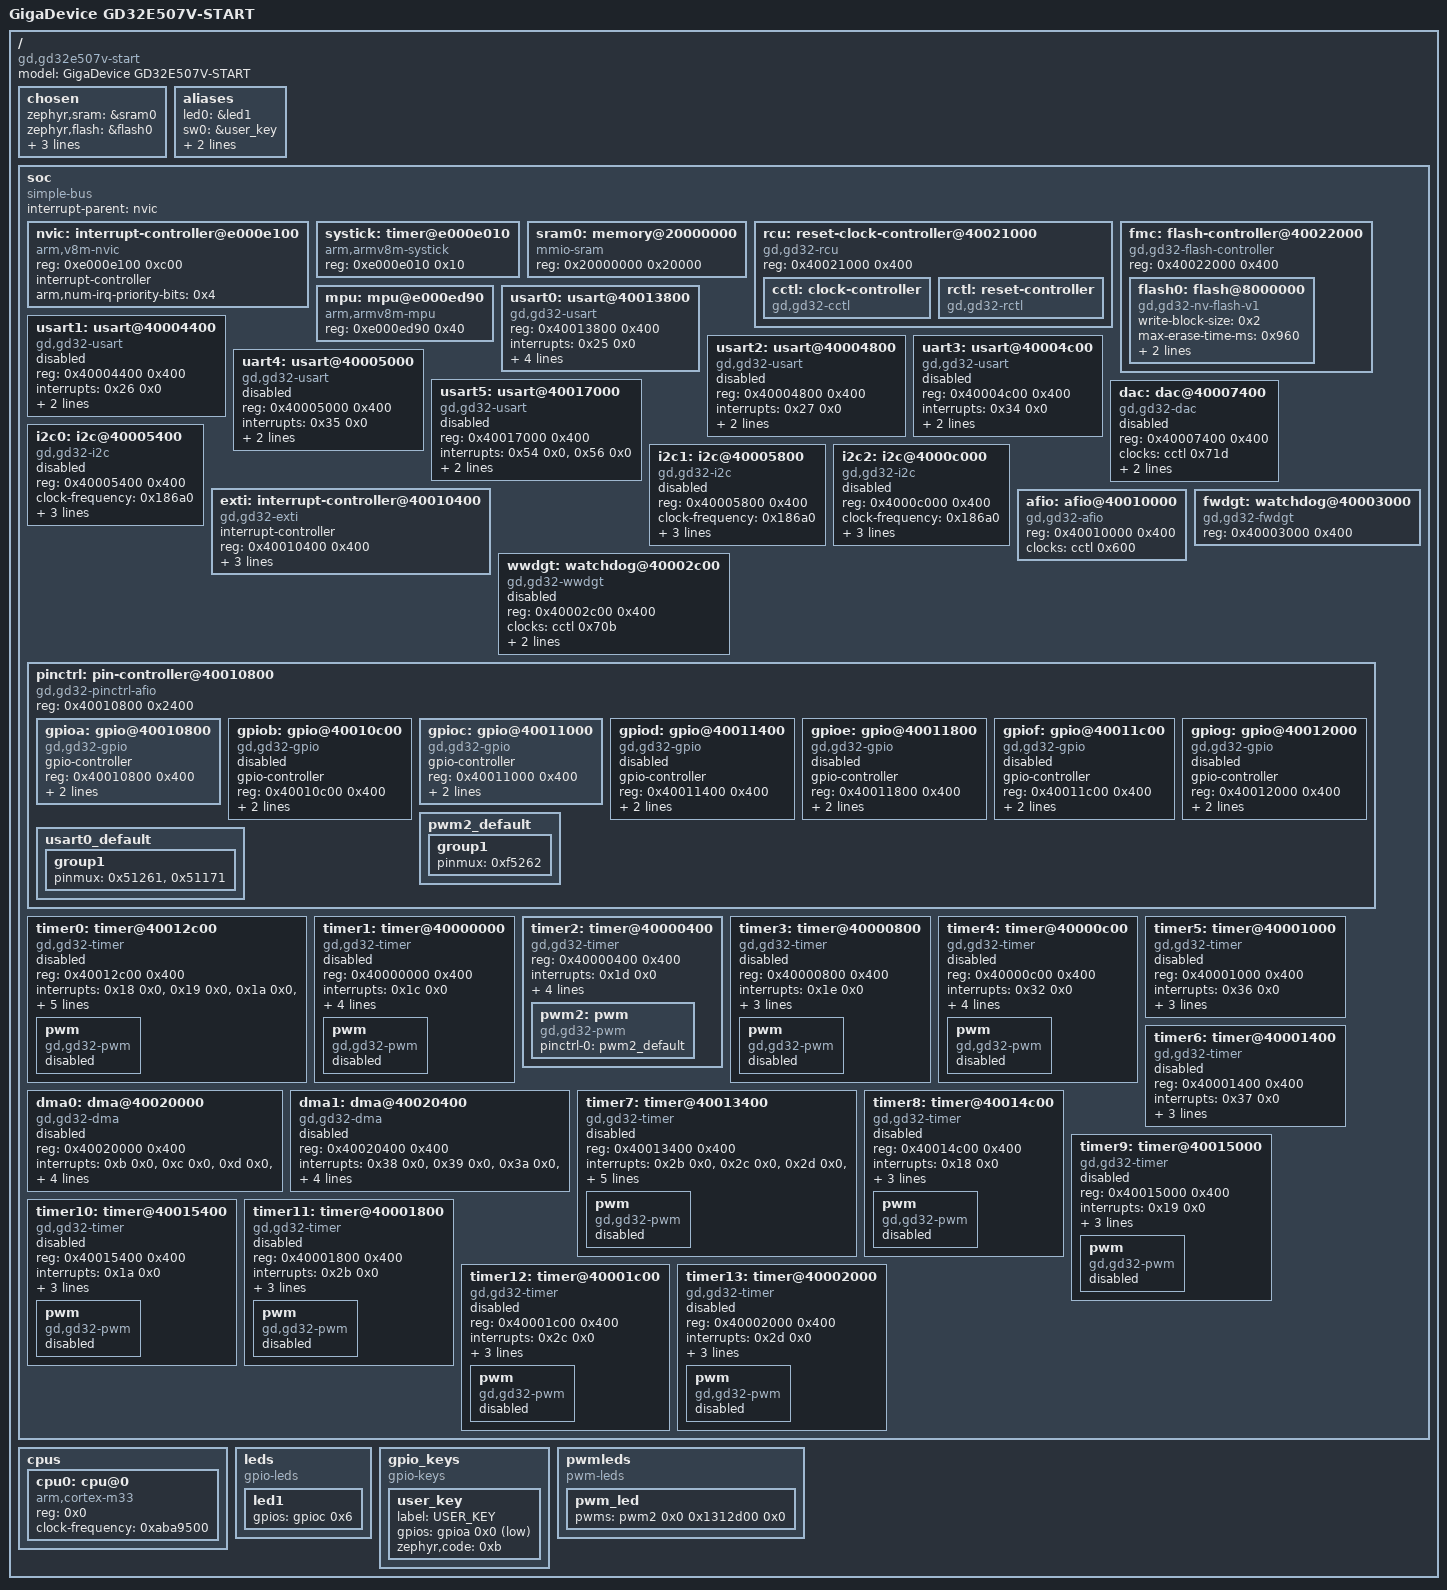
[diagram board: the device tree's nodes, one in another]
/dts-v1/;

/* node '/' defined in zephyr/dts/common/skeleton.dtsi:9 */
/ {
	#address-cells = < 0x1 >;             /* in zephyr/dts/common/skeleton.dtsi:10 */
	#size-cells = < 0x1 >;                /* in zephyr/dts/common/skeleton.dtsi:11 */
	model = "GigaDevice GD32E507V-START"; /* in zephyr/boards/gd/gd32e507v_start/gd32e507v_start.dts:13 */
	compatible = "gd,gd32e507v-start";    /* in zephyr/boards/gd/gd32e507v_start/gd32e507v_start.dts:14 */

	/* node '/chosen' defined in zephyr/dts/common/skeleton.dtsi:13 */
	chosen {
		zephyr,sram = &sram0;           /* in zephyr/boards/gd/gd32e507v_start/gd32e507v_start.dts:17 */
		zephyr,flash = &flash0;         /* in zephyr/boards/gd/gd32e507v_start/gd32e507v_start.dts:18 */
		zephyr,console = &usart0;       /* in zephyr/boards/gd/gd32e507v_start/gd32e507v_start.dts:19 */
		zephyr,shell-uart = &usart0;    /* in zephyr/boards/gd/gd32e507v_start/gd32e507v_start.dts:20 */
		zephyr,flash-controller = &fmc; /* in zephyr/boards/gd/gd32e507v_start/gd32e507v_start.dts:21 */
	};

	/* node '/aliases' defined in zephyr/dts/common/skeleton.dtsi:15 */
	aliases {
		led0 = &led1;        /* in zephyr/boards/gd/gd32e507v_start/gd32e507v_start.dts:51 */
		sw0 = &user_key;     /* in zephyr/boards/gd/gd32e507v_start/gd32e507v_start.dts:52 */
		pwm-led0 = &pwm_led; /* in zephyr/boards/gd/gd32e507v_start/gd32e507v_start.dts:53 */
		watchdog0 = &fwdgt;  /* in zephyr/boards/gd/gd32e507v_start/gd32e507v_start.dts:54 */
	};

	/* node '/soc' defined in zephyr/dts/arm/armv8-m.dtsi:6 */
	soc {
		#address-cells = < 0x1 >;     /* in zephyr/dts/arm/armv8-m.dtsi:7 */
		#size-cells = < 0x1 >;        /* in zephyr/dts/arm/armv8-m.dtsi:8 */
		compatible = "simple-bus";    /* in zephyr/dts/arm/armv8-m.dtsi:9 */
		interrupt-parent = < &nvic >; /* in zephyr/dts/arm/armv8-m.dtsi:10 */
		ranges;                       /* in zephyr/dts/arm/armv8-m.dtsi:11 */

		/* node '/soc/interrupt-controller@e000e100' defined in zephyr/dts/arm/armv8-m.dtsi:13 */
		nvic: interrupt-controller@e000e100 {
			#address-cells = < 0x1 >;            /* in zephyr/dts/arm/armv8-m.dtsi:14 */
			compatible = "arm,v8m-nvic";         /* in zephyr/dts/arm/armv8-m.dtsi:15 */
			reg = < 0xe000e100 0xc00 >;          /* in zephyr/dts/arm/armv8-m.dtsi:16 */
			interrupt-controller;                /* in zephyr/dts/arm/armv8-m.dtsi:17 */
			#interrupt-cells = < 0x2 >;          /* in zephyr/dts/arm/armv8-m.dtsi:18 */
			arm,num-irq-priority-bits = < 0x4 >; /* in zephyr/dts/arm/gd/gd32e50x/gd32e50x.dtsi:433 */
			phandle = < 0x1 >;                   /* in zephyr/dts/arm/armv8-m.dtsi:10 */
		};

		/* node '/soc/timer@e000e010' defined in zephyr/dts/arm/armv8-m.dtsi:21 */
		systick: timer@e000e010 {
			compatible = "arm,armv8m-systick"; /* in zephyr/dts/arm/armv8-m.dtsi:22 */
			reg = < 0xe000e010 0x10 >;         /* in zephyr/dts/arm/armv8-m.dtsi:23 */
		};

		/* node '/soc/memory@20000000' defined in zephyr/dts/arm/gd/gd32e50x/gd32e50x.dtsi:30 */
		sram0: memory@20000000 {
			compatible = "mmio-sram";     /* in zephyr/dts/arm/gd/gd32e50x/gd32e50x.dtsi:31 */
			reg = < 0x20000000 0x20000 >; /* in zephyr/dts/arm/gd/gd32e50x/gd32e507xe.dtsi:139 */
		};

		/* node '/soc/reset-clock-controller@40021000' defined in zephyr/dts/arm/gd/gd32e50x/gd32e50x.dtsi:34 */
		rcu: reset-clock-controller@40021000 {
			compatible = "gd,gd32-rcu"; /* in zephyr/dts/arm/gd/gd32e50x/gd32e50x.dtsi:35 */
			reg = < 0x40021000 0x400 >; /* in zephyr/dts/arm/gd/gd32e50x/gd32e50x.dtsi:36 */
			status = "okay";            /* in zephyr/dts/arm/gd/gd32e50x/gd32e50x.dtsi:37 */

			/* node '/soc/reset-clock-controller@40021000/clock-controller' defined in zephyr/dts/arm/gd/gd32e50x/gd32e50x.dtsi:39 */
			cctl: clock-controller {
				compatible = "gd,gd32-cctl"; /* in zephyr/dts/arm/gd/gd32e50x/gd32e50x.dtsi:40 */
				#clock-cells = < 0x1 >;      /* in zephyr/dts/arm/gd/gd32e50x/gd32e50x.dtsi:41 */
				status = "okay";             /* in zephyr/dts/arm/gd/gd32e50x/gd32e50x.dtsi:42 */
				phandle = < 0x2 >;           /* in zephyr/dts/arm/gd/gd32e50x/gd32e50x.dtsi:83 */
			};

			/* node '/soc/reset-clock-controller@40021000/reset-controller' defined in zephyr/dts/arm/gd/gd32e50x/gd32e50x.dtsi:45 */
			rctl: reset-controller {
				compatible = "gd,gd32-rctl"; /* in zephyr/dts/arm/gd/gd32e50x/gd32e50x.dtsi:46 */
				#reset-cells = < 0x1 >;      /* in zephyr/dts/arm/gd/gd32e50x/gd32e50x.dtsi:47 */
				status = "okay";             /* in zephyr/dts/arm/gd/gd32e50x/gd32e50x.dtsi:48 */
				phandle = < 0x3 >;           /* in zephyr/dts/arm/gd/gd32e50x/gd32e50x.dtsi:84 */
			};
		};

		/* node '/soc/flash-controller@40022000' defined in zephyr/dts/arm/gd/gd32e50x/gd32e50x.dtsi:52 */
		fmc: flash-controller@40022000 {
			compatible = "gd,gd32-flash-controller"; /* in zephyr/dts/arm/gd/gd32e50x/gd32e50x.dtsi:53 */
			reg = < 0x40022000 0x400 >;              /* in zephyr/dts/arm/gd/gd32e50x/gd32e50x.dtsi:54 */
			#address-cells = < 0x1 >;                /* in zephyr/dts/arm/gd/gd32e50x/gd32e50x.dtsi:56 */
			#size-cells = < 0x1 >;                   /* in zephyr/dts/arm/gd/gd32e50x/gd32e50x.dtsi:57 */

			/* node '/soc/flash-controller@40022000/flash@8000000' defined in zephyr/dts/arm/gd/gd32e50x/gd32e50x.dtsi:59 */
			flash0: flash@8000000 {
				compatible = "gd,gd32-nv-flash-v1",
				             "soc-nv-flash";        /* in zephyr/dts/arm/gd/gd32e50x/gd32e50x.dtsi:60 */
				write-block-size = < 0x2 >;         /* in zephyr/dts/arm/gd/gd32e50x/gd32e50x.dtsi:61 */
				max-erase-time-ms = < 0x960 >;      /* in zephyr/dts/arm/gd/gd32e50x/gd32e50x.dtsi:69 */
				page-size = < 0x2000 >;             /* in zephyr/dts/arm/gd/gd32e50x/gd32e50x.dtsi:70 */
				reg = < 0x8000000 0x80000 >;        /* in zephyr/dts/arm/gd/gd32e50x/gd32e507xe.dtsi:135 */
			};
		};

		/* node '/soc/mpu@e000ed90' defined in zephyr/dts/arm/gd/gd32e50x/gd32e50x.dtsi:74 */
		mpu: mpu@e000ed90 {
			compatible = "arm,armv8m-mpu"; /* in zephyr/dts/arm/gd/gd32e50x/gd32e50x.dtsi:75 */
			reg = < 0xe000ed90 0x40 >;     /* in zephyr/dts/arm/gd/gd32e50x/gd32e50x.dtsi:76 */
		};

		/* node '/soc/usart@40013800' defined in zephyr/dts/arm/gd/gd32e50x/gd32e50x.dtsi:79 */
		usart0: usart@40013800 {
			compatible = "gd,gd32-usart";    /* in zephyr/dts/arm/gd/gd32e50x/gd32e50x.dtsi:80 */
			reg = < 0x40013800 0x400 >;      /* in zephyr/dts/arm/gd/gd32e50x/gd32e50x.dtsi:81 */
			interrupts = < 0x25 0x0 >;       /* in zephyr/dts/arm/gd/gd32e50x/gd32e50x.dtsi:82 */
			clocks = < &cctl 0x60e >;        /* in zephyr/dts/arm/gd/gd32e50x/gd32e50x.dtsi:83 */
			resets = < &rctl 0x30e >;        /* in zephyr/dts/arm/gd/gd32e50x/gd32e50x.dtsi:84 */
			status = "okay";                 /* in zephyr/boards/gd/gd32e507v_start/gd32e507v_start.dts:67 */
			current-speed = < 0x1c200 >;     /* in zephyr/boards/gd/gd32e507v_start/gd32e507v_start.dts:68 */
			pinctrl-0 = < &usart0_default >; /* in zephyr/boards/gd/gd32e507v_start/gd32e507v_start.dts:69 */
			pinctrl-names = "default";       /* in zephyr/boards/gd/gd32e507v_start/gd32e507v_start.dts:70 */
		};

		/* node '/soc/usart@40004400' defined in zephyr/dts/arm/gd/gd32e50x/gd32e50x.dtsi:88 */
		usart1: usart@40004400 {
			compatible = "gd,gd32-usart"; /* in zephyr/dts/arm/gd/gd32e50x/gd32e50x.dtsi:89 */
			reg = < 0x40004400 0x400 >;   /* in zephyr/dts/arm/gd/gd32e50x/gd32e50x.dtsi:90 */
			interrupts = < 0x26 0x0 >;    /* in zephyr/dts/arm/gd/gd32e50x/gd32e50x.dtsi:91 */
			clocks = < &cctl 0x711 >;     /* in zephyr/dts/arm/gd/gd32e50x/gd32e50x.dtsi:92 */
			resets = < &rctl 0x411 >;     /* in zephyr/dts/arm/gd/gd32e50x/gd32e50x.dtsi:93 */
			status = "disabled";          /* in zephyr/dts/arm/gd/gd32e50x/gd32e50x.dtsi:94 */
		};

		/* node '/soc/usart@40004800' defined in zephyr/dts/arm/gd/gd32e50x/gd32e50x.dtsi:97 */
		usart2: usart@40004800 {
			compatible = "gd,gd32-usart"; /* in zephyr/dts/arm/gd/gd32e50x/gd32e50x.dtsi:98 */
			reg = < 0x40004800 0x400 >;   /* in zephyr/dts/arm/gd/gd32e50x/gd32e50x.dtsi:99 */
			interrupts = < 0x27 0x0 >;    /* in zephyr/dts/arm/gd/gd32e50x/gd32e50x.dtsi:100 */
			clocks = < &cctl 0x712 >;     /* in zephyr/dts/arm/gd/gd32e50x/gd32e50x.dtsi:101 */
			resets = < &rctl 0x412 >;     /* in zephyr/dts/arm/gd/gd32e50x/gd32e50x.dtsi:102 */
			status = "disabled";          /* in zephyr/dts/arm/gd/gd32e50x/gd32e50x.dtsi:103 */
		};

		/* node '/soc/usart@40004c00' defined in zephyr/dts/arm/gd/gd32e50x/gd32e50x.dtsi:106 */
		uart3: usart@40004c00 {
			compatible = "gd,gd32-usart"; /* in zephyr/dts/arm/gd/gd32e50x/gd32e50x.dtsi:107 */
			reg = < 0x40004c00 0x400 >;   /* in zephyr/dts/arm/gd/gd32e50x/gd32e50x.dtsi:108 */
			interrupts = < 0x34 0x0 >;    /* in zephyr/dts/arm/gd/gd32e50x/gd32e50x.dtsi:109 */
			clocks = < &cctl 0x713 >;     /* in zephyr/dts/arm/gd/gd32e50x/gd32e50x.dtsi:110 */
			resets = < &rctl 0x413 >;     /* in zephyr/dts/arm/gd/gd32e50x/gd32e50x.dtsi:111 */
			status = "disabled";          /* in zephyr/dts/arm/gd/gd32e50x/gd32e50x.dtsi:112 */
		};

		/* node '/soc/usart@40005000' defined in zephyr/dts/arm/gd/gd32e50x/gd32e50x.dtsi:115 */
		uart4: usart@40005000 {
			compatible = "gd,gd32-usart"; /* in zephyr/dts/arm/gd/gd32e50x/gd32e50x.dtsi:116 */
			reg = < 0x40005000 0x400 >;   /* in zephyr/dts/arm/gd/gd32e50x/gd32e50x.dtsi:117 */
			interrupts = < 0x35 0x0 >;    /* in zephyr/dts/arm/gd/gd32e50x/gd32e50x.dtsi:118 */
			clocks = < &cctl 0x714 >;     /* in zephyr/dts/arm/gd/gd32e50x/gd32e50x.dtsi:119 */
			resets = < &rctl 0x414 >;     /* in zephyr/dts/arm/gd/gd32e50x/gd32e50x.dtsi:120 */
			status = "disabled";          /* in zephyr/dts/arm/gd/gd32e50x/gd32e50x.dtsi:121 */
		};

		/* node '/soc/usart@40017000' defined in zephyr/dts/arm/gd/gd32e50x/gd32e50x.dtsi:124 */
		usart5: usart@40017000 {
			compatible = "gd,gd32-usart"; /* in zephyr/dts/arm/gd/gd32e50x/gd32e50x.dtsi:125 */
			reg = < 0x40017000 0x400 >;   /* in zephyr/dts/arm/gd/gd32e50x/gd32e50x.dtsi:126 */
			interrupts = < 0x54 0x0 >,
			             < 0x56 0x0 >;    /* in zephyr/dts/arm/gd/gd32e50x/gd32e50x.dtsi:127 */
			interrupt-names = "global",
			                  "wkup";     /* in zephyr/dts/arm/gd/gd32e50x/gd32e50x.dtsi:128 */
			clocks = < &cctl 0x61c >;     /* in zephyr/dts/arm/gd/gd32e50x/gd32e50x.dtsi:129 */
			resets = < &rctl 0x31c >;     /* in zephyr/dts/arm/gd/gd32e50x/gd32e50x.dtsi:130 */
			status = "disabled";          /* in zephyr/dts/arm/gd/gd32e50x/gd32e50x.dtsi:131 */
		};

		/* node '/soc/dac@40007400' defined in zephyr/dts/arm/gd/gd32e50x/gd32e50x.dtsi:134 */
		dac: dac@40007400 {
			compatible = "gd,gd32-dac";  /* in zephyr/dts/arm/gd/gd32e50x/gd32e50x.dtsi:135 */
			reg = < 0x40007400 0x400 >;  /* in zephyr/dts/arm/gd/gd32e50x/gd32e50x.dtsi:136 */
			clocks = < &cctl 0x71d >;    /* in zephyr/dts/arm/gd/gd32e50x/gd32e50x.dtsi:137 */
			resets = < &rctl 0x41d >;    /* in zephyr/dts/arm/gd/gd32e50x/gd32e50x.dtsi:138 */
			num-channels = < 0x2 >;      /* in zephyr/dts/arm/gd/gd32e50x/gd32e50x.dtsi:139 */
			status = "disabled";         /* in zephyr/dts/arm/gd/gd32e50x/gd32e50x.dtsi:140 */
			#io-channel-cells = < 0x1 >; /* in zephyr/dts/arm/gd/gd32e50x/gd32e50x.dtsi:141 */
		};

		/* node '/soc/i2c@40005400' defined in zephyr/dts/arm/gd/gd32e50x/gd32e50x.dtsi:144 */
		i2c0: i2c@40005400 {
			compatible = "gd,gd32-i2c";    /* in zephyr/dts/arm/gd/gd32e50x/gd32e50x.dtsi:145 */
			reg = < 0x40005400 0x400 >;    /* in zephyr/dts/arm/gd/gd32e50x/gd32e50x.dtsi:146 */
			#address-cells = < 0x1 >;      /* in zephyr/dts/arm/gd/gd32e50x/gd32e50x.dtsi:147 */
			#size-cells = < 0x0 >;         /* in zephyr/dts/arm/gd/gd32e50x/gd32e50x.dtsi:148 */
			clock-frequency = < 0x186a0 >; /* in zephyr/dts/arm/gd/gd32e50x/gd32e50x.dtsi:149 */
			interrupts = < 0x1f 0x0 >,
			             < 0x20 0x0 >;     /* in zephyr/dts/arm/gd/gd32e50x/gd32e50x.dtsi:150 */
			interrupt-names = "event",
			                  "error";     /* in zephyr/dts/arm/gd/gd32e50x/gd32e50x.dtsi:151 */
			clocks = < &cctl 0x715 >;      /* in zephyr/dts/arm/gd/gd32e50x/gd32e50x.dtsi:152 */
			resets = < &rctl 0x415 >;      /* in zephyr/dts/arm/gd/gd32e50x/gd32e50x.dtsi:153 */
			status = "disabled";           /* in zephyr/dts/arm/gd/gd32e50x/gd32e50x.dtsi:154 */
		};

		/* node '/soc/i2c@40005800' defined in zephyr/dts/arm/gd/gd32e50x/gd32e50x.dtsi:157 */
		i2c1: i2c@40005800 {
			compatible = "gd,gd32-i2c";    /* in zephyr/dts/arm/gd/gd32e50x/gd32e50x.dtsi:158 */
			reg = < 0x40005800 0x400 >;    /* in zephyr/dts/arm/gd/gd32e50x/gd32e50x.dtsi:159 */
			#address-cells = < 0x1 >;      /* in zephyr/dts/arm/gd/gd32e50x/gd32e50x.dtsi:160 */
			#size-cells = < 0x0 >;         /* in zephyr/dts/arm/gd/gd32e50x/gd32e50x.dtsi:161 */
			clock-frequency = < 0x186a0 >; /* in zephyr/dts/arm/gd/gd32e50x/gd32e50x.dtsi:162 */
			interrupts = < 0x21 0x0 >,
			             < 0x22 0x0 >;     /* in zephyr/dts/arm/gd/gd32e50x/gd32e50x.dtsi:163 */
			interrupt-names = "event",
			                  "error";     /* in zephyr/dts/arm/gd/gd32e50x/gd32e50x.dtsi:164 */
			clocks = < &cctl 0x716 >;      /* in zephyr/dts/arm/gd/gd32e50x/gd32e50x.dtsi:165 */
			resets = < &rctl 0x416 >;      /* in zephyr/dts/arm/gd/gd32e50x/gd32e50x.dtsi:166 */
			status = "disabled";           /* in zephyr/dts/arm/gd/gd32e50x/gd32e50x.dtsi:167 */
		};

		/* node '/soc/i2c@4000c000' defined in zephyr/dts/arm/gd/gd32e50x/gd32e50x.dtsi:170 */
		i2c2: i2c@4000c000 {
			compatible = "gd,gd32-i2c";    /* in zephyr/dts/arm/gd/gd32e50x/gd32e50x.dtsi:171 */
			reg = < 0x4000c000 0x400 >;    /* in zephyr/dts/arm/gd/gd32e50x/gd32e50x.dtsi:172 */
			#address-cells = < 0x1 >;      /* in zephyr/dts/arm/gd/gd32e50x/gd32e50x.dtsi:173 */
			#size-cells = < 0x0 >;         /* in zephyr/dts/arm/gd/gd32e50x/gd32e50x.dtsi:174 */
			clock-frequency = < 0x186a0 >; /* in zephyr/dts/arm/gd/gd32e50x/gd32e50x.dtsi:175 */
			interrupts = < 0x52 0x0 >,
			             < 0x53 0x0 >;     /* in zephyr/dts/arm/gd/gd32e50x/gd32e50x.dtsi:176 */
			interrupt-names = "event",
			                  "error";     /* in zephyr/dts/arm/gd/gd32e50x/gd32e50x.dtsi:177 */
			clocks = < &cctl 0x718 >;      /* in zephyr/dts/arm/gd/gd32e50x/gd32e50x.dtsi:178 */
			resets = < &rctl 0x418 >;      /* in zephyr/dts/arm/gd/gd32e50x/gd32e50x.dtsi:179 */
			status = "disabled";           /* in zephyr/dts/arm/gd/gd32e50x/gd32e50x.dtsi:180 */
		};

		/* node '/soc/interrupt-controller@40010400' defined in zephyr/dts/arm/gd/gd32e50x/gd32e50x.dtsi:183 */
		exti: interrupt-controller@40010400 {
			compatible = "gd,gd32-exti";   /* in zephyr/dts/arm/gd/gd32e50x/gd32e50x.dtsi:184 */
			interrupt-controller;          /* in zephyr/dts/arm/gd/gd32e50x/gd32e50x.dtsi:185 */
			#interrupt-cells = < 0x1 >;    /* in zephyr/dts/arm/gd/gd32e50x/gd32e50x.dtsi:186 */
			reg = < 0x40010400 0x400 >;    /* in zephyr/dts/arm/gd/gd32e50x/gd32e50x.dtsi:187 */
			num-lines = < 0x16 >;          /* in zephyr/dts/arm/gd/gd32e50x/gd32e50x.dtsi:188 */
			interrupts = < 0x6 0x0 >,
			             < 0x7 0x0 >,
			             < 0x8 0x0 >,
			             < 0x9 0x0 >,
			             < 0xa 0x0 >,
			             < 0x17 0x0 >,
			             < 0x28 0x0 >;     /* in zephyr/dts/arm/gd/gd32e50x/gd32e50x.dtsi:189 */
			interrupt-names = "line0",
			                  "line1",
			                  "line2",
			                  "line3",
			                  "line4",
			                  "line5-9",
			                  "line10-15"; /* in zephyr/dts/arm/gd/gd32e50x/gd32e50x.dtsi:191 */
			status = "okay";               /* in zephyr/dts/arm/gd/gd32e50x/gd32e50x.dtsi:193 */
		};

		/* node '/soc/afio@40010000' defined in zephyr/dts/arm/gd/gd32e50x/gd32e50x.dtsi:196 */
		afio: afio@40010000 {
			compatible = "gd,gd32-afio"; /* in zephyr/dts/arm/gd/gd32e50x/gd32e50x.dtsi:197 */
			reg = < 0x40010000 0x400 >;  /* in zephyr/dts/arm/gd/gd32e50x/gd32e50x.dtsi:198 */
			clocks = < &cctl 0x600 >;    /* in zephyr/dts/arm/gd/gd32e50x/gd32e50x.dtsi:199 */
			status = "okay";             /* in zephyr/dts/arm/gd/gd32e50x/gd32e50x.dtsi:200 */
		};

		/* node '/soc/watchdog@40003000' defined in zephyr/dts/arm/gd/gd32e50x/gd32e50x.dtsi:203 */
		fwdgt: watchdog@40003000 {
			compatible = "gd,gd32-fwdgt"; /* in zephyr/dts/arm/gd/gd32e50x/gd32e50x.dtsi:204 */
			reg = < 0x40003000 0x400 >;   /* in zephyr/dts/arm/gd/gd32e50x/gd32e50x.dtsi:205 */
			status = "okay";              /* in zephyr/boards/gd/gd32e507v_start/gd32e507v_start.dts:85 */
		};

		/* node '/soc/watchdog@40002c00' defined in zephyr/dts/arm/gd/gd32e50x/gd32e50x.dtsi:209 */
		wwdgt: watchdog@40002c00 {
			compatible = "gd,gd32-wwdgt"; /* in zephyr/dts/arm/gd/gd32e50x/gd32e50x.dtsi:210 */
			reg = < 0x40002c00 0x400 >;   /* in zephyr/dts/arm/gd/gd32e50x/gd32e50x.dtsi:211 */
			clocks = < &cctl 0x70b >;     /* in zephyr/dts/arm/gd/gd32e50x/gd32e50x.dtsi:212 */
			resets = < &rctl 0x40b >;     /* in zephyr/dts/arm/gd/gd32e50x/gd32e50x.dtsi:213 */
			interrupts = < 0x0 0x0 >;     /* in zephyr/dts/arm/gd/gd32e50x/gd32e50x.dtsi:214 */
			status = "disabled";          /* in zephyr/dts/arm/gd/gd32e50x/gd32e50x.dtsi:215 */
		};

		/* node '/soc/pin-controller@40010800' defined in zephyr/dts/arm/gd/gd32e50x/gd32e50x.dtsi:218 */
		pinctrl: pin-controller@40010800 {
			compatible = "gd,gd32-pinctrl-afio"; /* in zephyr/dts/arm/gd/gd32e50x/gd32e50x.dtsi:219 */
			reg = < 0x40010800 0x2400 >;         /* in zephyr/dts/arm/gd/gd32e50x/gd32e50x.dtsi:220 */
			#address-cells = < 0x1 >;            /* in zephyr/dts/arm/gd/gd32e50x/gd32e50x.dtsi:221 */
			#size-cells = < 0x1 >;               /* in zephyr/dts/arm/gd/gd32e50x/gd32e50x.dtsi:222 */
			status = "okay";                     /* in zephyr/dts/arm/gd/gd32e50x/gd32e50x.dtsi:223 */

			/* node '/soc/pin-controller@40010800/gpio@40010800' defined in zephyr/dts/arm/gd/gd32e50x/gd32e50x.dtsi:225 */
			gpioa: gpio@40010800 {
				compatible = "gd,gd32-gpio"; /* in zephyr/dts/arm/gd/gd32e50x/gd32e50x.dtsi:226 */
				gpio-controller;             /* in zephyr/dts/arm/gd/gd32e50x/gd32e50x.dtsi:227 */
				#gpio-cells = < 0x2 >;       /* in zephyr/dts/arm/gd/gd32e50x/gd32e50x.dtsi:228 */
				reg = < 0x40010800 0x400 >;  /* in zephyr/dts/arm/gd/gd32e50x/gd32e50x.dtsi:229 */
				clocks = < &cctl 0x602 >;    /* in zephyr/dts/arm/gd/gd32e50x/gd32e50x.dtsi:230 */
				resets = < &rctl 0x302 >;    /* in zephyr/dts/arm/gd/gd32e50x/gd32e50x.dtsi:231 */
				status = "okay";             /* in zephyr/boards/gd/gd32e507v_start/gd32e507v_start.dts:59 */
				phandle = < 0x7 >;           /* in zephyr/boards/gd/gd32e507v_start/gd32e507v_start.dts:37 */
			};

			/* node '/soc/pin-controller@40010800/gpio@40010c00' defined in zephyr/dts/arm/gd/gd32e50x/gd32e50x.dtsi:235 */
			gpiob: gpio@40010c00 {
				compatible = "gd,gd32-gpio"; /* in zephyr/dts/arm/gd/gd32e50x/gd32e50x.dtsi:236 */
				gpio-controller;             /* in zephyr/dts/arm/gd/gd32e50x/gd32e50x.dtsi:237 */
				#gpio-cells = < 0x2 >;       /* in zephyr/dts/arm/gd/gd32e50x/gd32e50x.dtsi:238 */
				reg = < 0x40010c00 0x400 >;  /* in zephyr/dts/arm/gd/gd32e50x/gd32e50x.dtsi:239 */
				clocks = < &cctl 0x603 >;    /* in zephyr/dts/arm/gd/gd32e50x/gd32e50x.dtsi:240 */
				resets = < &rctl 0x303 >;    /* in zephyr/dts/arm/gd/gd32e50x/gd32e50x.dtsi:241 */
				status = "disabled";         /* in zephyr/dts/arm/gd/gd32e50x/gd32e50x.dtsi:242 */
			};

			/* node '/soc/pin-controller@40010800/gpio@40011000' defined in zephyr/dts/arm/gd/gd32e50x/gd32e50x.dtsi:245 */
			gpioc: gpio@40011000 {
				compatible = "gd,gd32-gpio"; /* in zephyr/dts/arm/gd/gd32e50x/gd32e50x.dtsi:246 */
				gpio-controller;             /* in zephyr/dts/arm/gd/gd32e50x/gd32e50x.dtsi:247 */
				#gpio-cells = < 0x2 >;       /* in zephyr/dts/arm/gd/gd32e50x/gd32e50x.dtsi:248 */
				reg = < 0x40011000 0x400 >;  /* in zephyr/dts/arm/gd/gd32e50x/gd32e50x.dtsi:249 */
				clocks = < &cctl 0x604 >;    /* in zephyr/dts/arm/gd/gd32e50x/gd32e50x.dtsi:250 */
				resets = < &rctl 0x304 >;    /* in zephyr/dts/arm/gd/gd32e50x/gd32e50x.dtsi:251 */
				status = "okay";             /* in zephyr/boards/gd/gd32e507v_start/gd32e507v_start.dts:63 */
				phandle = < 0x6 >;           /* in zephyr/boards/gd/gd32e507v_start/gd32e507v_start.dts:28 */
			};

			/* node '/soc/pin-controller@40010800/gpio@40011400' defined in zephyr/dts/arm/gd/gd32e50x/gd32e50x.dtsi:255 */
			gpiod: gpio@40011400 {
				compatible = "gd,gd32-gpio"; /* in zephyr/dts/arm/gd/gd32e50x/gd32e50x.dtsi:256 */
				gpio-controller;             /* in zephyr/dts/arm/gd/gd32e50x/gd32e50x.dtsi:257 */
				#gpio-cells = < 0x2 >;       /* in zephyr/dts/arm/gd/gd32e50x/gd32e50x.dtsi:258 */
				reg = < 0x40011400 0x400 >;  /* in zephyr/dts/arm/gd/gd32e50x/gd32e50x.dtsi:259 */
				clocks = < &cctl 0x605 >;    /* in zephyr/dts/arm/gd/gd32e50x/gd32e50x.dtsi:260 */
				resets = < &rctl 0x305 >;    /* in zephyr/dts/arm/gd/gd32e50x/gd32e50x.dtsi:261 */
				status = "disabled";         /* in zephyr/dts/arm/gd/gd32e50x/gd32e50x.dtsi:262 */
			};

			/* node '/soc/pin-controller@40010800/gpio@40011800' defined in zephyr/dts/arm/gd/gd32e50x/gd32e50x.dtsi:265 */
			gpioe: gpio@40011800 {
				compatible = "gd,gd32-gpio"; /* in zephyr/dts/arm/gd/gd32e50x/gd32e50x.dtsi:266 */
				gpio-controller;             /* in zephyr/dts/arm/gd/gd32e50x/gd32e50x.dtsi:267 */
				#gpio-cells = < 0x2 >;       /* in zephyr/dts/arm/gd/gd32e50x/gd32e50x.dtsi:268 */
				reg = < 0x40011800 0x400 >;  /* in zephyr/dts/arm/gd/gd32e50x/gd32e50x.dtsi:269 */
				clocks = < &cctl 0x606 >;    /* in zephyr/dts/arm/gd/gd32e50x/gd32e50x.dtsi:270 */
				resets = < &rctl 0x306 >;    /* in zephyr/dts/arm/gd/gd32e50x/gd32e50x.dtsi:271 */
				status = "disabled";         /* in zephyr/dts/arm/gd/gd32e50x/gd32e50x.dtsi:272 */
			};

			/* node '/soc/pin-controller@40010800/gpio@40011c00' defined in zephyr/dts/arm/gd/gd32e50x/gd32e50x.dtsi:275 */
			gpiof: gpio@40011c00 {
				compatible = "gd,gd32-gpio"; /* in zephyr/dts/arm/gd/gd32e50x/gd32e50x.dtsi:276 */
				gpio-controller;             /* in zephyr/dts/arm/gd/gd32e50x/gd32e50x.dtsi:277 */
				#gpio-cells = < 0x2 >;       /* in zephyr/dts/arm/gd/gd32e50x/gd32e50x.dtsi:278 */
				reg = < 0x40011c00 0x400 >;  /* in zephyr/dts/arm/gd/gd32e50x/gd32e50x.dtsi:279 */
				clocks = < &cctl 0x607 >;    /* in zephyr/dts/arm/gd/gd32e50x/gd32e50x.dtsi:280 */
				resets = < &rctl 0x307 >;    /* in zephyr/dts/arm/gd/gd32e50x/gd32e50x.dtsi:281 */
				status = "disabled";         /* in zephyr/dts/arm/gd/gd32e50x/gd32e50x.dtsi:282 */
			};

			/* node '/soc/pin-controller@40010800/gpio@40012000' defined in zephyr/dts/arm/gd/gd32e50x/gd32e50x.dtsi:285 */
			gpiog: gpio@40012000 {
				compatible = "gd,gd32-gpio"; /* in zephyr/dts/arm/gd/gd32e50x/gd32e50x.dtsi:286 */
				gpio-controller;             /* in zephyr/dts/arm/gd/gd32e50x/gd32e50x.dtsi:287 */
				#gpio-cells = < 0x2 >;       /* in zephyr/dts/arm/gd/gd32e50x/gd32e50x.dtsi:288 */
				reg = < 0x40012000 0x400 >;  /* in zephyr/dts/arm/gd/gd32e50x/gd32e50x.dtsi:289 */
				clocks = < &cctl 0x608 >;    /* in zephyr/dts/arm/gd/gd32e50x/gd32e50x.dtsi:290 */
				resets = < &rctl 0x308 >;    /* in zephyr/dts/arm/gd/gd32e50x/gd32e50x.dtsi:291 */
				status = "disabled";         /* in zephyr/dts/arm/gd/gd32e50x/gd32e50x.dtsi:292 */
			};

			/* node '/soc/pin-controller@40010800/usart0_default' defined in zephyr/boards/gd/gd32e507v_start/gd32e507v_start-pinctrl.dtsi:9 */
			usart0_default: usart0_default {
				phandle = < 0x4 >; /* in zephyr/boards/gd/gd32e507v_start/gd32e507v_start.dts:69 */

				/* node '/soc/pin-controller@40010800/usart0_default/group1' defined in zephyr/boards/gd/gd32e507v_start/gd32e507v_start-pinctrl.dtsi:10 */
				group1 {
					pinmux = < 0x51261 >,
					         < 0x51171 >; /* in zephyr/boards/gd/gd32e507v_start/gd32e507v_start-pinctrl.dtsi:11 */
				};
			};

			/* node '/soc/pin-controller@40010800/pwm2_default' defined in zephyr/boards/gd/gd32e507v_start/gd32e507v_start-pinctrl.dtsi:15 */
			pwm2_default: pwm2_default {
				phandle = < 0x5 >; /* in zephyr/boards/gd/gd32e507v_start/gd32e507v_start.dts:79 */

				/* node '/soc/pin-controller@40010800/pwm2_default/group1' defined in zephyr/boards/gd/gd32e507v_start/gd32e507v_start-pinctrl.dtsi:16 */
				group1 {
					pinmux = < 0xf5262 >; /* in zephyr/boards/gd/gd32e507v_start/gd32e507v_start-pinctrl.dtsi:17 */
				};
			};
		};

		/* node '/soc/timer@40012c00' defined in zephyr/dts/arm/gd/gd32e50x/gd32e50x.dtsi:296 */
		timer0: timer@40012c00 {
			compatible = "gd,gd32-timer"; /* in zephyr/dts/arm/gd/gd32e50x/gd32e50x.dtsi:297 */
			reg = < 0x40012c00 0x400 >;   /* in zephyr/dts/arm/gd/gd32e50x/gd32e50x.dtsi:298 */
			interrupts = < 0x18 0x0 >,
			             < 0x19 0x0 >,
			             < 0x1a 0x0 >,
			             < 0x1b 0x0 >;    /* in zephyr/dts/arm/gd/gd32e50x/gd32e50x.dtsi:299 */
			interrupt-names = "brk",
			                  "up",
			                  "trgcom",
			                  "cc";       /* in zephyr/dts/arm/gd/gd32e50x/gd32e50x.dtsi:300 */
			clocks = < &cctl 0x60b >;     /* in zephyr/dts/arm/gd/gd32e50x/gd32e50x.dtsi:301 */
			resets = < &rctl 0x30b >;     /* in zephyr/dts/arm/gd/gd32e50x/gd32e50x.dtsi:302 */
			is-advanced;                  /* in zephyr/dts/arm/gd/gd32e50x/gd32e50x.dtsi:303 */
			channels = < 0x4 >;           /* in zephyr/dts/arm/gd/gd32e50x/gd32e50x.dtsi:304 */
			status = "disabled";          /* in zephyr/dts/arm/gd/gd32e50x/gd32e50x.dtsi:305 */

			/* node '/soc/timer@40012c00/pwm' defined in zephyr/dts/arm/gd/gd32e50x/gd32e50x.dtsi:307 */
			pwm {
				compatible = "gd,gd32-pwm"; /* in zephyr/dts/arm/gd/gd32e50x/gd32e50x.dtsi:308 */
				status = "disabled";        /* in zephyr/dts/arm/gd/gd32e50x/gd32e50x.dtsi:309 */
				#pwm-cells = < 0x3 >;       /* in zephyr/dts/arm/gd/gd32e50x/gd32e50x.dtsi:310 */
			};
		};

		/* node '/soc/timer@40000000' defined in zephyr/dts/arm/gd/gd32e50x/gd32e50x.dtsi:314 */
		timer1: timer@40000000 {
			compatible = "gd,gd32-timer"; /* in zephyr/dts/arm/gd/gd32e50x/gd32e50x.dtsi:315 */
			reg = < 0x40000000 0x400 >;   /* in zephyr/dts/arm/gd/gd32e50x/gd32e50x.dtsi:316 */
			interrupts = < 0x1c 0x0 >;    /* in zephyr/dts/arm/gd/gd32e50x/gd32e50x.dtsi:317 */
			interrupt-names = "global";   /* in zephyr/dts/arm/gd/gd32e50x/gd32e50x.dtsi:318 */
			clocks = < &cctl 0x700 >;     /* in zephyr/dts/arm/gd/gd32e50x/gd32e50x.dtsi:319 */
			resets = < &rctl 0x400 >;     /* in zephyr/dts/arm/gd/gd32e50x/gd32e50x.dtsi:320 */
			is-32bit;                     /* in zephyr/dts/arm/gd/gd32e50x/gd32e50x.dtsi:321 */
			channels = < 0x4 >;           /* in zephyr/dts/arm/gd/gd32e50x/gd32e50x.dtsi:322 */
			status = "disabled";          /* in zephyr/dts/arm/gd/gd32e50x/gd32e50x.dtsi:323 */

			/* node '/soc/timer@40000000/pwm' defined in zephyr/dts/arm/gd/gd32e50x/gd32e50x.dtsi:325 */
			pwm {
				compatible = "gd,gd32-pwm"; /* in zephyr/dts/arm/gd/gd32e50x/gd32e50x.dtsi:326 */
				status = "disabled";        /* in zephyr/dts/arm/gd/gd32e50x/gd32e50x.dtsi:327 */
				#pwm-cells = < 0x3 >;       /* in zephyr/dts/arm/gd/gd32e50x/gd32e50x.dtsi:328 */
			};
		};

		/* node '/soc/timer@40000400' defined in zephyr/dts/arm/gd/gd32e50x/gd32e50x.dtsi:332 */
		timer2: timer@40000400 {
			compatible = "gd,gd32-timer"; /* in zephyr/dts/arm/gd/gd32e50x/gd32e50x.dtsi:333 */
			reg = < 0x40000400 0x400 >;   /* in zephyr/dts/arm/gd/gd32e50x/gd32e50x.dtsi:334 */
			interrupts = < 0x1d 0x0 >;    /* in zephyr/dts/arm/gd/gd32e50x/gd32e50x.dtsi:335 */
			interrupt-names = "global";   /* in zephyr/dts/arm/gd/gd32e50x/gd32e50x.dtsi:336 */
			clocks = < &cctl 0x701 >;     /* in zephyr/dts/arm/gd/gd32e50x/gd32e50x.dtsi:337 */
			resets = < &rctl 0x401 >;     /* in zephyr/dts/arm/gd/gd32e50x/gd32e50x.dtsi:338 */
			channels = < 0x4 >;           /* in zephyr/dts/arm/gd/gd32e50x/gd32e50x.dtsi:339 */
			status = "okay";              /* in zephyr/boards/gd/gd32e507v_start/gd32e507v_start.dts:74 */
			prescaler = < 0x100 >;        /* in zephyr/boards/gd/gd32e507v_start/gd32e507v_start.dts:75 */

			/* node '/soc/timer@40000400/pwm' defined in zephyr/dts/arm/gd/gd32e50x/gd32e50x.dtsi:342 */
			pwm2: pwm {
				compatible = "gd,gd32-pwm";    /* in zephyr/dts/arm/gd/gd32e50x/gd32e50x.dtsi:343 */
				#pwm-cells = < 0x3 >;          /* in zephyr/dts/arm/gd/gd32e50x/gd32e50x.dtsi:345 */
				status = "okay";               /* in zephyr/boards/gd/gd32e507v_start/gd32e507v_start.dts:78 */
				pinctrl-0 = < &pwm2_default >; /* in zephyr/boards/gd/gd32e507v_start/gd32e507v_start.dts:79 */
				pinctrl-names = "default";     /* in zephyr/boards/gd/gd32e507v_start/gd32e507v_start.dts:80 */
				phandle = < 0x8 >;             /* in zephyr/boards/gd/gd32e507v_start/gd32e507v_start.dts:46 */
			};
		};

		/* node '/soc/timer@40000800' defined in zephyr/dts/arm/gd/gd32e50x/gd32e50x.dtsi:349 */
		timer3: timer@40000800 {
			compatible = "gd,gd32-timer"; /* in zephyr/dts/arm/gd/gd32e50x/gd32e50x.dtsi:350 */
			reg = < 0x40000800 0x400 >;   /* in zephyr/dts/arm/gd/gd32e50x/gd32e50x.dtsi:351 */
			interrupts = < 0x1e 0x0 >;    /* in zephyr/dts/arm/gd/gd32e50x/gd32e50x.dtsi:352 */
			interrupt-names = "global";   /* in zephyr/dts/arm/gd/gd32e50x/gd32e50x.dtsi:353 */
			clocks = < &cctl 0x702 >;     /* in zephyr/dts/arm/gd/gd32e50x/gd32e50x.dtsi:354 */
			resets = < &rctl 0x402 >;     /* in zephyr/dts/arm/gd/gd32e50x/gd32e50x.dtsi:355 */
			channels = < 0x4 >;           /* in zephyr/dts/arm/gd/gd32e50x/gd32e50x.dtsi:356 */
			status = "disabled";          /* in zephyr/dts/arm/gd/gd32e50x/gd32e50x.dtsi:357 */

			/* node '/soc/timer@40000800/pwm' defined in zephyr/dts/arm/gd/gd32e50x/gd32e50x.dtsi:359 */
			pwm {
				compatible = "gd,gd32-pwm"; /* in zephyr/dts/arm/gd/gd32e50x/gd32e50x.dtsi:360 */
				status = "disabled";        /* in zephyr/dts/arm/gd/gd32e50x/gd32e50x.dtsi:361 */
				#pwm-cells = < 0x3 >;       /* in zephyr/dts/arm/gd/gd32e50x/gd32e50x.dtsi:362 */
			};
		};

		/* node '/soc/timer@40000c00' defined in zephyr/dts/arm/gd/gd32e50x/gd32e50x.dtsi:366 */
		timer4: timer@40000c00 {
			compatible = "gd,gd32-timer"; /* in zephyr/dts/arm/gd/gd32e50x/gd32e50x.dtsi:367 */
			reg = < 0x40000c00 0x400 >;   /* in zephyr/dts/arm/gd/gd32e50x/gd32e50x.dtsi:368 */
			interrupts = < 0x32 0x0 >;    /* in zephyr/dts/arm/gd/gd32e50x/gd32e50x.dtsi:369 */
			interrupt-names = "global";   /* in zephyr/dts/arm/gd/gd32e50x/gd32e50x.dtsi:370 */
			clocks = < &cctl 0x703 >;     /* in zephyr/dts/arm/gd/gd32e50x/gd32e50x.dtsi:371 */
			resets = < &rctl 0x402 >;     /* in zephyr/dts/arm/gd/gd32e50x/gd32e50x.dtsi:372 */
			is-32bit;                     /* in zephyr/dts/arm/gd/gd32e50x/gd32e50x.dtsi:373 */
			channels = < 0x4 >;           /* in zephyr/dts/arm/gd/gd32e50x/gd32e50x.dtsi:374 */
			status = "disabled";          /* in zephyr/dts/arm/gd/gd32e50x/gd32e50x.dtsi:375 */

			/* node '/soc/timer@40000c00/pwm' defined in zephyr/dts/arm/gd/gd32e50x/gd32e50x.dtsi:377 */
			pwm {
				compatible = "gd,gd32-pwm"; /* in zephyr/dts/arm/gd/gd32e50x/gd32e50x.dtsi:378 */
				status = "disabled";        /* in zephyr/dts/arm/gd/gd32e50x/gd32e50x.dtsi:379 */
				#pwm-cells = < 0x3 >;       /* in zephyr/dts/arm/gd/gd32e50x/gd32e50x.dtsi:380 */
			};
		};

		/* node '/soc/timer@40001000' defined in zephyr/dts/arm/gd/gd32e50x/gd32e50x.dtsi:384 */
		timer5: timer@40001000 {
			compatible = "gd,gd32-timer"; /* in zephyr/dts/arm/gd/gd32e50x/gd32e50x.dtsi:385 */
			reg = < 0x40001000 0x400 >;   /* in zephyr/dts/arm/gd/gd32e50x/gd32e50x.dtsi:386 */
			interrupts = < 0x36 0x0 >;    /* in zephyr/dts/arm/gd/gd32e50x/gd32e50x.dtsi:387 */
			interrupt-names = "global";   /* in zephyr/dts/arm/gd/gd32e50x/gd32e50x.dtsi:388 */
			clocks = < &cctl 0x704 >;     /* in zephyr/dts/arm/gd/gd32e50x/gd32e50x.dtsi:389 */
			resets = < &rctl 0x404 >;     /* in zephyr/dts/arm/gd/gd32e50x/gd32e50x.dtsi:390 */
			channels = < 0x0 >;           /* in zephyr/dts/arm/gd/gd32e50x/gd32e50x.dtsi:391 */
			status = "disabled";          /* in zephyr/dts/arm/gd/gd32e50x/gd32e50x.dtsi:392 */
		};

		/* node '/soc/timer@40001400' defined in zephyr/dts/arm/gd/gd32e50x/gd32e50x.dtsi:395 */
		timer6: timer@40001400 {
			compatible = "gd,gd32-timer"; /* in zephyr/dts/arm/gd/gd32e50x/gd32e50x.dtsi:396 */
			reg = < 0x40001400 0x400 >;   /* in zephyr/dts/arm/gd/gd32e50x/gd32e50x.dtsi:397 */
			interrupts = < 0x37 0x0 >;    /* in zephyr/dts/arm/gd/gd32e50x/gd32e50x.dtsi:398 */
			interrupt-names = "global";   /* in zephyr/dts/arm/gd/gd32e50x/gd32e50x.dtsi:399 */
			clocks = < &cctl 0x705 >;     /* in zephyr/dts/arm/gd/gd32e50x/gd32e50x.dtsi:400 */
			resets = < &rctl 0x405 >;     /* in zephyr/dts/arm/gd/gd32e50x/gd32e50x.dtsi:401 */
			channels = < 0x0 >;           /* in zephyr/dts/arm/gd/gd32e50x/gd32e50x.dtsi:402 */
			status = "disabled";          /* in zephyr/dts/arm/gd/gd32e50x/gd32e50x.dtsi:403 */
		};

		/* node '/soc/dma@40020000' defined in zephyr/dts/arm/gd/gd32e50x/gd32e50x.dtsi:406 */
		dma0: dma@40020000 {
			compatible = "gd,gd32-dma"; /* in zephyr/dts/arm/gd/gd32e50x/gd32e50x.dtsi:407 */
			reg = < 0x40020000 0x400 >; /* in zephyr/dts/arm/gd/gd32e50x/gd32e50x.dtsi:408 */
			interrupts = < 0xb 0x0 >,
			             < 0xc 0x0 >,
			             < 0xd 0x0 >,
			             < 0xe 0x0 >,
			             < 0xf 0x0 >,
			             < 0x10 0x0 >,
			             < 0x11 0x0 >;  /* in zephyr/dts/arm/gd/gd32e50x/gd32e50x.dtsi:409 */
			clocks = < &cctl 0x500 >;   /* in zephyr/dts/arm/gd/gd32e50x/gd32e50x.dtsi:411 */
			dma-channels = < 0x7 >;     /* in zephyr/dts/arm/gd/gd32e50x/gd32e50x.dtsi:412 */
			gd,mem2mem;                 /* in zephyr/dts/arm/gd/gd32e50x/gd32e50x.dtsi:413 */
			#dma-cells = < 0x2 >;       /* in zephyr/dts/arm/gd/gd32e50x/gd32e50x.dtsi:414 */
			status = "disabled";        /* in zephyr/dts/arm/gd/gd32e50x/gd32e50x.dtsi:415 */
		};

		/* node '/soc/dma@40020400' defined in zephyr/dts/arm/gd/gd32e50x/gd32e50x.dtsi:418 */
		dma1: dma@40020400 {
			compatible = "gd,gd32-dma"; /* in zephyr/dts/arm/gd/gd32e50x/gd32e50x.dtsi:419 */
			reg = < 0x40020400 0x400 >; /* in zephyr/dts/arm/gd/gd32e50x/gd32e50x.dtsi:420 */
			interrupts = < 0x38 0x0 >,
			             < 0x39 0x0 >,
			             < 0x3a 0x0 >,
			             < 0x3b 0x0 >,
			             < 0x3c 0x0 >;  /* in zephyr/dts/arm/gd/gd32e50x/gd32e50x.dtsi:421 */
			clocks = < &cctl 0x501 >;   /* in zephyr/dts/arm/gd/gd32e50x/gd32e50x.dtsi:423 */
			dma-channels = < 0x5 >;     /* in zephyr/dts/arm/gd/gd32e50x/gd32e50x.dtsi:424 */
			gd,mem2mem;                 /* in zephyr/dts/arm/gd/gd32e50x/gd32e50x.dtsi:425 */
			#dma-cells = < 0x2 >;       /* in zephyr/dts/arm/gd/gd32e50x/gd32e50x.dtsi:426 */
			status = "disabled";        /* in zephyr/dts/arm/gd/gd32e50x/gd32e50x.dtsi:427 */
		};

		/* node '/soc/timer@40013400' defined in zephyr/dts/arm/gd/gd32e50x/gd32e507xe.dtsi:12 */
		timer7: timer@40013400 {
			compatible = "gd,gd32-timer"; /* in zephyr/dts/arm/gd/gd32e50x/gd32e507xe.dtsi:13 */
			reg = < 0x40013400 0x400 >;   /* in zephyr/dts/arm/gd/gd32e50x/gd32e507xe.dtsi:14 */
			interrupts = < 0x2b 0x0 >,
			             < 0x2c 0x0 >,
			             < 0x2d 0x0 >,
			             < 0x2e 0x0 >;    /* in zephyr/dts/arm/gd/gd32e50x/gd32e507xe.dtsi:15 */
			interrupt-names = "brk",
			                  "up",
			                  "trgcom",
			                  "cc";       /* in zephyr/dts/arm/gd/gd32e50x/gd32e507xe.dtsi:16 */
			clocks = < &cctl 0x60d >;     /* in zephyr/dts/arm/gd/gd32e50x/gd32e507xe.dtsi:17 */
			resets = < &rctl 0x30d >;     /* in zephyr/dts/arm/gd/gd32e50x/gd32e507xe.dtsi:18 */
			is-advanced;                  /* in zephyr/dts/arm/gd/gd32e50x/gd32e507xe.dtsi:19 */
			channels = < 0x4 >;           /* in zephyr/dts/arm/gd/gd32e50x/gd32e507xe.dtsi:20 */
			status = "disabled";          /* in zephyr/dts/arm/gd/gd32e50x/gd32e507xe.dtsi:21 */

			/* node '/soc/timer@40013400/pwm' defined in zephyr/dts/arm/gd/gd32e50x/gd32e507xe.dtsi:23 */
			pwm {
				compatible = "gd,gd32-pwm"; /* in zephyr/dts/arm/gd/gd32e50x/gd32e507xe.dtsi:24 */
				status = "disabled";        /* in zephyr/dts/arm/gd/gd32e50x/gd32e507xe.dtsi:25 */
				#pwm-cells = < 0x3 >;       /* in zephyr/dts/arm/gd/gd32e50x/gd32e507xe.dtsi:26 */
			};
		};

		/* node '/soc/timer@40014c00' defined in zephyr/dts/arm/gd/gd32e50x/gd32e507xe.dtsi:30 */
		timer8: timer@40014c00 {
			compatible = "gd,gd32-timer"; /* in zephyr/dts/arm/gd/gd32e50x/gd32e507xe.dtsi:31 */
			reg = < 0x40014c00 0x400 >;   /* in zephyr/dts/arm/gd/gd32e50x/gd32e507xe.dtsi:32 */
			interrupts = < 0x18 0x0 >;    /* in zephyr/dts/arm/gd/gd32e50x/gd32e507xe.dtsi:33 */
			interrupt-names = "global";   /* in zephyr/dts/arm/gd/gd32e50x/gd32e507xe.dtsi:34 */
			clocks = < &cctl 0x613 >;     /* in zephyr/dts/arm/gd/gd32e50x/gd32e507xe.dtsi:35 */
			resets = < &rctl 0x313 >;     /* in zephyr/dts/arm/gd/gd32e50x/gd32e507xe.dtsi:36 */
			channels = < 0x2 >;           /* in zephyr/dts/arm/gd/gd32e50x/gd32e507xe.dtsi:37 */
			status = "disabled";          /* in zephyr/dts/arm/gd/gd32e50x/gd32e507xe.dtsi:38 */

			/* node '/soc/timer@40014c00/pwm' defined in zephyr/dts/arm/gd/gd32e50x/gd32e507xe.dtsi:40 */
			pwm {
				compatible = "gd,gd32-pwm"; /* in zephyr/dts/arm/gd/gd32e50x/gd32e507xe.dtsi:41 */
				status = "disabled";        /* in zephyr/dts/arm/gd/gd32e50x/gd32e507xe.dtsi:42 */
				#pwm-cells = < 0x3 >;       /* in zephyr/dts/arm/gd/gd32e50x/gd32e507xe.dtsi:43 */
			};
		};

		/* node '/soc/timer@40015000' defined in zephyr/dts/arm/gd/gd32e50x/gd32e507xe.dtsi:47 */
		timer9: timer@40015000 {
			compatible = "gd,gd32-timer"; /* in zephyr/dts/arm/gd/gd32e50x/gd32e507xe.dtsi:48 */
			reg = < 0x40015000 0x400 >;   /* in zephyr/dts/arm/gd/gd32e50x/gd32e507xe.dtsi:49 */
			interrupts = < 0x19 0x0 >;    /* in zephyr/dts/arm/gd/gd32e50x/gd32e507xe.dtsi:50 */
			interrupt-names = "global";   /* in zephyr/dts/arm/gd/gd32e50x/gd32e507xe.dtsi:51 */
			clocks = < &cctl 0x614 >;     /* in zephyr/dts/arm/gd/gd32e50x/gd32e507xe.dtsi:52 */
			resets = < &rctl 0x314 >;     /* in zephyr/dts/arm/gd/gd32e50x/gd32e507xe.dtsi:53 */
			channels = < 0x1 >;           /* in zephyr/dts/arm/gd/gd32e50x/gd32e507xe.dtsi:54 */
			status = "disabled";          /* in zephyr/dts/arm/gd/gd32e50x/gd32e507xe.dtsi:55 */

			/* node '/soc/timer@40015000/pwm' defined in zephyr/dts/arm/gd/gd32e50x/gd32e507xe.dtsi:57 */
			pwm {
				compatible = "gd,gd32-pwm"; /* in zephyr/dts/arm/gd/gd32e50x/gd32e507xe.dtsi:58 */
				status = "disabled";        /* in zephyr/dts/arm/gd/gd32e50x/gd32e507xe.dtsi:59 */
				#pwm-cells = < 0x3 >;       /* in zephyr/dts/arm/gd/gd32e50x/gd32e507xe.dtsi:60 */
			};
		};

		/* node '/soc/timer@40015400' defined in zephyr/dts/arm/gd/gd32e50x/gd32e507xe.dtsi:64 */
		timer10: timer@40015400 {
			compatible = "gd,gd32-timer"; /* in zephyr/dts/arm/gd/gd32e50x/gd32e507xe.dtsi:65 */
			reg = < 0x40015400 0x400 >;   /* in zephyr/dts/arm/gd/gd32e50x/gd32e507xe.dtsi:66 */
			interrupts = < 0x1a 0x0 >;    /* in zephyr/dts/arm/gd/gd32e50x/gd32e507xe.dtsi:67 */
			interrupt-names = "global";   /* in zephyr/dts/arm/gd/gd32e50x/gd32e507xe.dtsi:68 */
			clocks = < &cctl 0x615 >;     /* in zephyr/dts/arm/gd/gd32e50x/gd32e507xe.dtsi:69 */
			resets = < &rctl 0x315 >;     /* in zephyr/dts/arm/gd/gd32e50x/gd32e507xe.dtsi:70 */
			channels = < 0x1 >;           /* in zephyr/dts/arm/gd/gd32e50x/gd32e507xe.dtsi:71 */
			status = "disabled";          /* in zephyr/dts/arm/gd/gd32e50x/gd32e507xe.dtsi:72 */

			/* node '/soc/timer@40015400/pwm' defined in zephyr/dts/arm/gd/gd32e50x/gd32e507xe.dtsi:74 */
			pwm {
				compatible = "gd,gd32-pwm"; /* in zephyr/dts/arm/gd/gd32e50x/gd32e507xe.dtsi:75 */
				status = "disabled";        /* in zephyr/dts/arm/gd/gd32e50x/gd32e507xe.dtsi:76 */
				#pwm-cells = < 0x3 >;       /* in zephyr/dts/arm/gd/gd32e50x/gd32e507xe.dtsi:77 */
			};
		};

		/* node '/soc/timer@40001800' defined in zephyr/dts/arm/gd/gd32e50x/gd32e507xe.dtsi:81 */
		timer11: timer@40001800 {
			compatible = "gd,gd32-timer"; /* in zephyr/dts/arm/gd/gd32e50x/gd32e507xe.dtsi:82 */
			reg = < 0x40001800 0x400 >;   /* in zephyr/dts/arm/gd/gd32e50x/gd32e507xe.dtsi:83 */
			interrupts = < 0x2b 0x0 >;    /* in zephyr/dts/arm/gd/gd32e50x/gd32e507xe.dtsi:84 */
			interrupt-names = "global";   /* in zephyr/dts/arm/gd/gd32e50x/gd32e507xe.dtsi:85 */
			clocks = < &cctl 0x706 >;     /* in zephyr/dts/arm/gd/gd32e50x/gd32e507xe.dtsi:86 */
			resets = < &rctl 0x406 >;     /* in zephyr/dts/arm/gd/gd32e50x/gd32e507xe.dtsi:87 */
			channels = < 0x2 >;           /* in zephyr/dts/arm/gd/gd32e50x/gd32e507xe.dtsi:88 */
			status = "disabled";          /* in zephyr/dts/arm/gd/gd32e50x/gd32e507xe.dtsi:89 */

			/* node '/soc/timer@40001800/pwm' defined in zephyr/dts/arm/gd/gd32e50x/gd32e507xe.dtsi:91 */
			pwm {
				compatible = "gd,gd32-pwm"; /* in zephyr/dts/arm/gd/gd32e50x/gd32e507xe.dtsi:92 */
				status = "disabled";        /* in zephyr/dts/arm/gd/gd32e50x/gd32e507xe.dtsi:93 */
				#pwm-cells = < 0x3 >;       /* in zephyr/dts/arm/gd/gd32e50x/gd32e507xe.dtsi:94 */
			};
		};

		/* node '/soc/timer@40001c00' defined in zephyr/dts/arm/gd/gd32e50x/gd32e507xe.dtsi:98 */
		timer12: timer@40001c00 {
			compatible = "gd,gd32-timer"; /* in zephyr/dts/arm/gd/gd32e50x/gd32e507xe.dtsi:99 */
			reg = < 0x40001c00 0x400 >;   /* in zephyr/dts/arm/gd/gd32e50x/gd32e507xe.dtsi:100 */
			interrupts = < 0x2c 0x0 >;    /* in zephyr/dts/arm/gd/gd32e50x/gd32e507xe.dtsi:101 */
			interrupt-names = "global";   /* in zephyr/dts/arm/gd/gd32e50x/gd32e507xe.dtsi:102 */
			clocks = < &cctl 0x707 >;     /* in zephyr/dts/arm/gd/gd32e50x/gd32e507xe.dtsi:103 */
			resets = < &rctl 0x407 >;     /* in zephyr/dts/arm/gd/gd32e50x/gd32e507xe.dtsi:104 */
			channels = < 0x1 >;           /* in zephyr/dts/arm/gd/gd32e50x/gd32e507xe.dtsi:105 */
			status = "disabled";          /* in zephyr/dts/arm/gd/gd32e50x/gd32e507xe.dtsi:106 */

			/* node '/soc/timer@40001c00/pwm' defined in zephyr/dts/arm/gd/gd32e50x/gd32e507xe.dtsi:108 */
			pwm {
				compatible = "gd,gd32-pwm"; /* in zephyr/dts/arm/gd/gd32e50x/gd32e507xe.dtsi:109 */
				status = "disabled";        /* in zephyr/dts/arm/gd/gd32e50x/gd32e507xe.dtsi:110 */
				#pwm-cells = < 0x3 >;       /* in zephyr/dts/arm/gd/gd32e50x/gd32e507xe.dtsi:111 */
			};
		};

		/* node '/soc/timer@40002000' defined in zephyr/dts/arm/gd/gd32e50x/gd32e507xe.dtsi:115 */
		timer13: timer@40002000 {
			compatible = "gd,gd32-timer"; /* in zephyr/dts/arm/gd/gd32e50x/gd32e507xe.dtsi:116 */
			reg = < 0x40002000 0x400 >;   /* in zephyr/dts/arm/gd/gd32e50x/gd32e507xe.dtsi:117 */
			interrupts = < 0x2d 0x0 >;    /* in zephyr/dts/arm/gd/gd32e50x/gd32e507xe.dtsi:118 */
			interrupt-names = "global";   /* in zephyr/dts/arm/gd/gd32e50x/gd32e507xe.dtsi:119 */
			clocks = < &cctl 0x708 >;     /* in zephyr/dts/arm/gd/gd32e50x/gd32e507xe.dtsi:120 */
			resets = < &rctl 0x408 >;     /* in zephyr/dts/arm/gd/gd32e50x/gd32e507xe.dtsi:121 */
			channels = < 0x1 >;           /* in zephyr/dts/arm/gd/gd32e50x/gd32e507xe.dtsi:122 */
			status = "disabled";          /* in zephyr/dts/arm/gd/gd32e50x/gd32e507xe.dtsi:123 */

			/* node '/soc/timer@40002000/pwm' defined in zephyr/dts/arm/gd/gd32e50x/gd32e507xe.dtsi:125 */
			pwm {
				compatible = "gd,gd32-pwm"; /* in zephyr/dts/arm/gd/gd32e50x/gd32e507xe.dtsi:126 */
				status = "disabled";        /* in zephyr/dts/arm/gd/gd32e50x/gd32e507xe.dtsi:127 */
				#pwm-cells = < 0x3 >;       /* in zephyr/dts/arm/gd/gd32e50x/gd32e507xe.dtsi:128 */
			};
		};
	};

	/* node '/cpus' defined in zephyr/dts/arm/gd/gd32e50x/gd32e50x.dtsi:16 */
	cpus {
		#address-cells = < 0x1 >; /* in zephyr/dts/arm/gd/gd32e50x/gd32e50x.dtsi:17 */
		#size-cells = < 0x0 >;    /* in zephyr/dts/arm/gd/gd32e50x/gd32e50x.dtsi:18 */

		/* node '/cpus/cpu@0' defined in zephyr/dts/arm/gd/gd32e50x/gd32e50x.dtsi:20 */
		cpu0: cpu@0 {
			compatible = "arm,cortex-m33";   /* in zephyr/dts/arm/gd/gd32e50x/gd32e50x.dtsi:21 */
			reg = < 0x0 >;                   /* in zephyr/dts/arm/gd/gd32e50x/gd32e50x.dtsi:22 */
			#address-cells = < 0x1 >;        /* in zephyr/dts/arm/gd/gd32e50x/gd32e50x.dtsi:23 */
			#size-cells = < 0x1 >;           /* in zephyr/dts/arm/gd/gd32e50x/gd32e50x.dtsi:24 */
			clock-frequency = < 0xaba9500 >; /* in zephyr/dts/arm/gd/gd32e50x/gd32e50x.dtsi:25 */
		};
	};

	/* node '/leds' defined in zephyr/boards/gd/gd32e507v_start/gd32e507v_start.dts:24 */
	leds {
		compatible = "gpio-leds"; /* in zephyr/boards/gd/gd32e507v_start/gd32e507v_start.dts:25 */

		/* node '/leds/led1' defined in zephyr/boards/gd/gd32e507v_start/gd32e507v_start.dts:27 */
		led1: led1 {
			gpios = < &gpioc 0x6 0x0 >; /* in zephyr/boards/gd/gd32e507v_start/gd32e507v_start.dts:28 */
		};
	};

	/* node '/gpio_keys' defined in zephyr/boards/gd/gd32e507v_start/gd32e507v_start.dts:32 */
	gpio_keys {
		compatible = "gpio-keys"; /* in zephyr/boards/gd/gd32e507v_start/gd32e507v_start.dts:33 */

		/* node '/gpio_keys/user_key' defined in zephyr/boards/gd/gd32e507v_start/gd32e507v_start.dts:35 */
		user_key: user_key {
			label = "USER_KEY";         /* in zephyr/boards/gd/gd32e507v_start/gd32e507v_start.dts:36 */
			gpios = < &gpioa 0x0 0x1 >; /* in zephyr/boards/gd/gd32e507v_start/gd32e507v_start.dts:37 */
			zephyr,code = < 0xb >;      /* in zephyr/boards/gd/gd32e507v_start/gd32e507v_start.dts:38 */
		};
	};

	/* node '/pwmleds' defined in zephyr/boards/gd/gd32e507v_start/gd32e507v_start.dts:42 */
	pwmleds {
		compatible = "pwm-leds"; /* in zephyr/boards/gd/gd32e507v_start/gd32e507v_start.dts:43 */

		/* node '/pwmleds/pwm_led' defined in zephyr/boards/gd/gd32e507v_start/gd32e507v_start.dts:45 */
		pwm_led: pwm_led {
			pwms = < &pwm2 0x0 0x1312d00 0x0 >; /* in zephyr/boards/gd/gd32e507v_start/gd32e507v_start.dts:46 */
		};
	};
};
